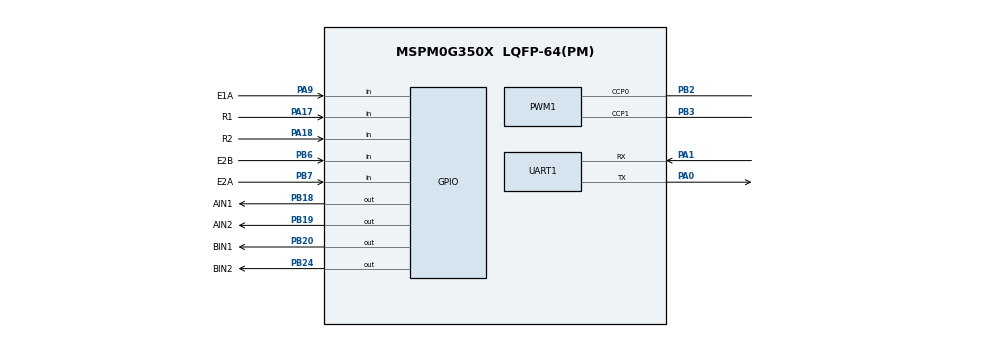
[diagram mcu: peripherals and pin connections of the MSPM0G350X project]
/**
 * @cliArgs --device "MSPM0G350X" --part "Default" --package "LQFP-64(PM)" --product "mspm0_sdk@2.03.00.07"
 * @versions {"tool":"1.22.0+3893"}
 */

/**
 * Import the modules used in this configuration.
 */
const GPIO    = scripting.addModule("/ti/driverlib/GPIO", {}, false);
const GPIO1   = GPIO.addInstance();
const GPIO2   = GPIO.addInstance();
const GPIO3   = GPIO.addInstance();
const GPIO4   = GPIO.addInstance();
const GPIO5   = GPIO.addInstance();
const GPIO6   = GPIO.addInstance();
const GPIO7   = GPIO.addInstance();
const GPIO8   = GPIO.addInstance();
const GPIO9   = GPIO.addInstance();
const PWM     = scripting.addModule("/ti/driverlib/PWM", {}, false);
const PWM1    = PWM.addInstance();
const SYSCTL  = scripting.addModule("/ti/driverlib/SYSCTL");
const SYSTICK = scripting.addModule("/ti/driverlib/SYSTICK");
const TIMER   = scripting.addModule("/ti/driverlib/TIMER", {}, false);
const TIMER1  = TIMER.addInstance();
const TIMER2  = TIMER.addInstance();
const UART    = scripting.addModule("/ti/driverlib/UART", {}, false);
const UART1   = UART.addInstance();

/**
 * Write custom configuration values to the imported modules.
 */
const gate7  = system.clockTree["MFCLKGATE"];
gate7.enable = true;

GPIO1.port                               = "PORTA";
GPIO1.$name                              = "LED";
GPIO1.associatedPins.create(2);
GPIO1.associatedPins[0].internalResistor = "PULL_DOWN";
GPIO1.associatedPins[0].assignedPin      = "26";
GPIO1.associatedPins[0].$name            = "BLUE";
GPIO1.associatedPins[1].assignedPin      = "27";
GPIO1.associatedPins[1].$name            = "GREEN";

const Board = scripting.addModule("/ti/driverlib/Board", {}, false);

GPIO2.$name                              = "KEY";
GPIO2.associatedPins.create(3);
GPIO2.associatedPins[0].direction        = "INPUT";
GPIO2.associatedPins[0].internalResistor = "PULL_UP";
GPIO2.associatedPins[0].inputFilter      = "8_CYCLES";
GPIO2.associatedPins[0].assignedPin      = "02";
GPIO2.associatedPins[0].assignedPort     = "PORTA";
GPIO2.associatedPins[0].$name            = "LapNum";
GPIO2.associatedPins[1].direction        = "INPUT";
GPIO2.associatedPins[1].internalResistor = "PULL_UP";
GPIO2.associatedPins[1].inputFilter      = "8_CYCLES";
GPIO2.associatedPins[1].assignedPin      = "31";
GPIO2.associatedPins[1].assignedPort     = "PORTA";
GPIO2.associatedPins[1].$name            = "TaskNum";
GPIO2.associatedPins[2].direction        = "INPUT";
GPIO2.associatedPins[2].assignedPort     = "PORTB";
GPIO2.associatedPins[2].assignedPin      = "09";
GPIO2.associatedPins[2].internalResistor = "PULL_UP";
GPIO2.associatedPins[2].$name            = "TotalStart";

GPIO3.port                           = "PORTA";
GPIO3.$name                          = "BEEP";
GPIO3.associatedPins[0].assignedPin  = "23";
GPIO3.associatedPins[0].initialValue = "SET";
GPIO3.associatedPins[0].$name        = "ONE";

GPIO4.$name                          = "Motor_left";
GPIO4.port                           = "PORTB";
GPIO4.associatedPins.create(2);
GPIO4.associatedPins[0].initialValue = "SET";
GPIO4.associatedPins[0].$name        = "AIN1";
GPIO4.associatedPins[0].assignedPin  = "18";
GPIO4.associatedPins[0].pin.$assign  = "PB18";
GPIO4.associatedPins[1].$name        = "AIN2";
GPIO4.associatedPins[1].initialValue = "SET";
GPIO4.associatedPins[1].assignedPin  = "19";
GPIO4.associatedPins[1].pin.$assign  = "PB19";

GPIO5.$name                          = "Motor_right";
GPIO5.associatedPins.create(2);
GPIO5.associatedPins[0].$name        = "BIN1";
GPIO5.associatedPins[0].initialValue = "SET";
GPIO5.associatedPins[0].assignedPort = "PORTB";
GPIO5.associatedPins[0].assignedPin  = "20";
GPIO5.associatedPins[0].pin.$assign  = "PB20";
GPIO5.associatedPins[1].$name        = "BIN2";
GPIO5.associatedPins[1].initialValue = "SET";
GPIO5.associatedPins[1].assignedPort = "PORTB";
GPIO5.associatedPins[1].assignedPin  = "24";
GPIO5.associatedPins[1].pin.$assign  = "PB24";

GPIO6.$name                               = "Encoder_left";
GPIO6.port                                = "PORTA";
GPIO6.associatedPins.create(2);
GPIO6.associatedPins[0].direction         = "INPUT";
GPIO6.associatedPins[0].$name             = "E1A";
GPIO6.associatedPins[0].assignedPin       = "9";
GPIO6.associatedPins[0].interruptEn       = true;
GPIO6.associatedPins[0].interruptPriority = "0";
GPIO6.associatedPins[0].polarity          = "RISE";
GPIO6.associatedPins[0].pin.$assign       = "PA9";
GPIO6.associatedPins[1].$name             = "E1B";
GPIO6.associatedPins[1].direction         = "INPUT";
GPIO6.associatedPins[1].assignedPin       = "8";
GPIO6.associatedPins[1].interruptEn       = true;
GPIO6.associatedPins[1].interruptPriority = "0";
GPIO6.associatedPins[1].polarity          = "RISE";

GPIO7.$name                               = "Encoder_right";
GPIO7.port                                = "PORTB";
GPIO7.associatedPins.create(2);
GPIO7.associatedPins[0].$name             = "E2A";
GPIO7.associatedPins[0].direction         = "INPUT";
GPIO7.associatedPins[0].interruptEn       = true;
GPIO7.associatedPins[0].assignedPin       = "7";
GPIO7.associatedPins[0].interruptPriority = "0";
GPIO7.associatedPins[0].polarity          = "RISE";
GPIO7.associatedPins[0].pin.$assign       = "PB7";
GPIO7.associatedPins[1].$name             = "E2B";
GPIO7.associatedPins[1].direction         = "INPUT";
GPIO7.associatedPins[1].interruptEn       = true;
GPIO7.associatedPins[1].assignedPin       = "6";
GPIO7.associatedPins[1].interruptPriority = "0";
GPIO7.associatedPins[1].polarity          = "RISE";
GPIO7.associatedPins[1].pin.$assign       = "PB6";

GPIO8.port                          = "PORTA";
GPIO8.$name                         = "Gray_IOA";
GPIO8.associatedPins.create(6);
GPIO8.associatedPins[0].direction   = "INPUT";
GPIO8.associatedPins[0].assignedPin = "16";
GPIO8.associatedPins[0].$name       = "L3";
GPIO8.associatedPins[1].direction   = "INPUT";
GPIO8.associatedPins[1].assignedPin = "12";
GPIO8.associatedPins[1].$name       = "L2";
GPIO8.associatedPins[2].direction   = "INPUT";
GPIO8.associatedPins[2].assignedPin = "13";
GPIO8.associatedPins[2].$name       = "L1";
GPIO8.associatedPins[3].direction   = "INPUT";
GPIO8.associatedPins[3].assignedPin = "15";
GPIO8.associatedPins[3].$name       = "M";
GPIO8.associatedPins[4].direction   = "INPUT";
GPIO8.associatedPins[4].assignedPin = "17";
GPIO8.associatedPins[4].$name       = "R1";
GPIO8.associatedPins[4].pin.$assign = "PA17";
GPIO8.associatedPins[5].direction   = "INPUT";
GPIO8.associatedPins[5].assignedPin = "18";
GPIO8.associatedPins[5].$name       = "R2";
GPIO8.associatedPins[5].pin.$assign = "PA18";

GPIO9.port                          = "PORTB";
GPIO9.$name                         = "Gray_IOB";
GPIO9.associatedPins[0].direction   = "INPUT";
GPIO9.associatedPins[0].assignedPin = "08";
GPIO9.associatedPins[0].$name       = "R3";

PWM1.$name                              = "PWM";
PWM1.clockDivider                       = 8;
PWM1.pwmMode                            = "EDGE_ALIGN_UP";
PWM1.timerStartTimer                    = true;
PWM1.clockPrescale                      = 4;
PWM1.peripheral.$assign                 = "TIMG6";
PWM1.peripheral.ccp0Pin.$assign         = "PB2";
PWM1.peripheral.ccp1Pin.$assign         = "PB3";
PWM1.PWM_CHANNEL_0.$name                = "ti_driverlib_pwm_PWMTimerCC0";
PWM1.PWM_CHANNEL_1.$name                = "ti_driverlib_pwm_PWMTimerCC1";
PWM1.ccp0PinConfig.direction            = scripting.forceWrite("OUTPUT");
PWM1.ccp0PinConfig.hideOutputInversion  = scripting.forceWrite(false);
PWM1.ccp0PinConfig.onlyInternalResistor = scripting.forceWrite(false);
PWM1.ccp0PinConfig.passedPeripheralType = scripting.forceWrite("Digital");
PWM1.ccp0PinConfig.$name                = "ti_driverlib_gpio_GPIOPinGeneric2";
PWM1.ccp1PinConfig.direction            = scripting.forceWrite("OUTPUT");
PWM1.ccp1PinConfig.hideOutputInversion  = scripting.forceWrite(false);
PWM1.ccp1PinConfig.onlyInternalResistor = scripting.forceWrite(false);
PWM1.ccp1PinConfig.passedPeripheralType = scripting.forceWrite("Digital");
PWM1.ccp1PinConfig.$name                = "ti_driverlib_gpio_GPIOPinGeneric3";

SYSCTL.forceDefaultClkConfig = true;
SYSCTL.clockTreeEn           = true;

SYSTICK.periodEnable      = true;
SYSTICK.systickEnable     = true;
SYSTICK.interruptPriority = "0";
SYSTICK.period            = 32;

TIMER1.$name              = "TIMER_0";
TIMER1.timerClkDiv        = 8;
TIMER1.timerClkPrescale   = 100;
TIMER1.timerMode          = "PERIODIC";
TIMER1.interrupts         = ["ZERO"];
TIMER1.timerStartTimer    = true;
TIMER1.timerPeriod        = "10ms";
TIMER1.interruptPriority  = "0";
TIMER1.peripheral.$assign = "TIMA0";

TIMER2.$name              = "TIMER_1";
TIMER2.timerStartTimer    = true;
TIMER2.timerMode          = "PERIODIC";
TIMER2.timerClkDiv        = 8;
TIMER2.timerClkPrescale   = 100;
TIMER2.interrupts         = ["LOAD"];
TIMER2.interruptPriority  = "1";
TIMER2.timerPeriod        = "10ms";
TIMER2.peripheral.$assign = "TIMG0";

UART1.$name                    = "UART_0";
UART1.targetBaudRate           = 115200;
UART1.enabledInterrupts        = ["RX"];
UART1.peripheral.$assign       = "UART0";
UART1.peripheral.rxPin.$assign = "PA1";
UART1.peripheral.txPin.$assign = "PA0";
UART1.txPinConfig.$name        = "ti_driverlib_gpio_GPIOPinGeneric4";
UART1.rxPinConfig.$name        = "ti_driverlib_gpio_GPIOPinGeneric5";

/**
 * Pinmux solution for unlocked pins/peripherals. This ensures that minor changes to the automatic solver in a future
 * version of the tool will not impact the pinmux you originally saw.  These lines can be completely deleted in order to
 * re-solve from scratch.
 */
GPIO1.associatedPins[0].pin.$suggestSolution = "PA26";
GPIO1.associatedPins[1].pin.$suggestSolution = "PA27";
Board.peripheral.$suggestSolution            = "DEBUGSS";
Board.peripheral.swclkPin.$suggestSolution   = "PA20";
Board.peripheral.swdioPin.$suggestSolution   = "PA19";
GPIO2.associatedPins[0].pin.$suggestSolution = "PA2";
GPIO2.associatedPins[1].pin.$suggestSolution = "PA31";
GPIO2.associatedPins[2].pin.$suggestSolution = "PB9";
GPIO3.associatedPins[0].pin.$suggestSolution = "PA23";
GPIO6.associatedPins[1].pin.$suggestSolution = "PA8";
GPIO8.associatedPins[0].pin.$suggestSolution = "PA16";
GPIO8.associatedPins[1].pin.$suggestSolution = "PA12";
GPIO8.associatedPins[2].pin.$suggestSolution = "PA13";
GPIO8.associatedPins[3].pin.$suggestSolution = "PA15";
GPIO9.associatedPins[0].pin.$suggestSolution = "PB8";
